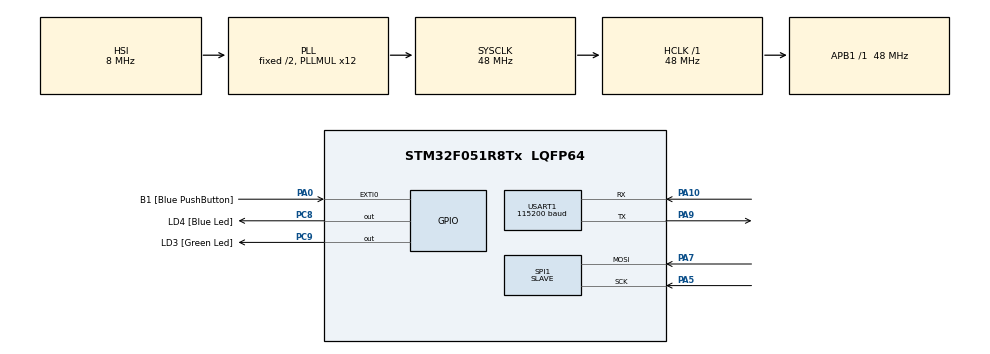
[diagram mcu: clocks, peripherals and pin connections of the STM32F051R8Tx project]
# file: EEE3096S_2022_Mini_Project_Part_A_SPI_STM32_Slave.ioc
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Dma.Request0=SPI1_RX
Dma.SPI1_RX.0.Direction=DMA_PERIPH_TO_MEMORY
Dma.SPI1_RX.0.Instance=DMA1_Channel2
Dma.SPI1_RX.0.MemDataAlignment=DMA_MDATAALIGN_BYTE
Dma.SPI1_RX.0.MemInc=DMA_MINC_ENABLE
Dma.SPI1_RX.0.Mode=DMA_CIRCULAR
Dma.SPI1_RX.0.PeriphDataAlignment=DMA_PDATAALIGN_BYTE
Dma.SPI1_RX.0.PeriphInc=DMA_PINC_DISABLE
Dma.SPI1_RX.0.Priority=DMA_PRIORITY_LOW
Mcu.Family=STM32F0
Mcu.Name=STM32F051R8Tx
Mcu.Package=LQFP64
NVIC.DMA1_Channel2_3_IRQn=true\:0\:0\:false\:false\:true\:false\:true\:true
NVIC.SPI1_IRQn=true\:0\:0\:false\:false\:true\:true\:true\:true
PA0.GPIO_Label=B1 [Blue PushButton]
PA0.GPIO_ModeDefaultEXTI=GPIO_MODE_EVT_RISING
PA0.Signal=GPXTI0
PA10.Mode=Asynchronous
PA10.Signal=USART1_RX
PA13.GPIO_Label=SWDIO
PA13.Mode=Serial_Wire
PA13.Signal=SYS_SWDIO
PA14.GPIO_Label=SWCLK
PA14.Mode=Serial_Wire
PA14.Signal=SYS_SWCLK
PA5.Mode=RX_Only_Simplex_Unidirect_Slave
PA5.Signal=SPI1_SCK
PA7.Mode=RX_Only_Simplex_Unidirect_Slave
PA7.Signal=SPI1_MOSI
PA9.Mode=Asynchronous
PA9.Signal=USART1_TX
PC8.GPIO_Label=LD4 [Blue Led]
PC8.Signal=GPIO_Output
PC9.GPIO_Label=LD3 [Green Led]
PC9.Signal=GPIO_Output
ProjectManager.HeapSize=0x200
ProjectManager.StackSize=0x400
ProjectManager.TargetToolchain=STM32CubeIDE
RCC.AHBFreq_Value=48000000
RCC.APB1Freq_Value=48000000
RCC.APB1TimFreq_Value=48000000
RCC.HCLKFreq_Value=48000000
RCC.PLLMUL=RCC_PLL_MUL12
RCC.SYSCLKFreq_VALUE=48000000
RCC.SYSCLKSource=RCC_SYSCLKSOURCE_PLLCLK
SPI1.DataSize=SPI_DATASIZE_8BIT
SPI1.Direction=SPI_DIRECTION_2LINES_RXONLY
SPI1.Mode=SPI_MODE_SLAVE
SPI1.VirtualType=VM_SLAVE
USART1.BaudRate=115200
USART1.VirtualMode-Asynchronous=VM_ASYNC
board=STM32F0DISCOVERY

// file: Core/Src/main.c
/* USER CODE BEGIN Header */
/**
  ******************************************************************************
  * @file           : main.c
  * @brief          : Main program body
  ******************************************************************************
  * @attention
  *
  * Copyright (c) 2022 STMicroelectronics.
  * All rights reserved.
  *
  * This software is licensed under terms that can be found in the LICENSE file
  * in the root directory of this software component.
  * If no LICENSE file comes with this software, it is provided AS-IS.
  *
  ******************************************************************************
  */
/* USER CODE END Header */
#include "main.h"

SPI_HandleTypeDef hspi1;
DMA_HandleTypeDef hdma_spi1_rx;

UART_HandleTypeDef huart1;
uint8_t RX_Data[1652] = {0};

void SystemClock_Config(void);
static void MX_GPIO_Init(void);
static void MX_DMA_Init(void);
static void MX_SPI1_Init(void);
static void MX_USART1_UART_Init(void);

int main(void)
{

  /* MCU Configuration--------------------------------------------------------*/

  /* Reset of all peripherals, Initializes the Flash interface and the Systick. */
  HAL_Init();

  /* Configure the system clock */
  SystemClock_Config();

  /* Initialize all configured peripherals */
  MX_GPIO_Init();
  MX_DMA_Init();
  MX_SPI1_Init();
  MX_USART1_UART_Init();
  /* USER CODE BEGIN 2 */
  // Receive SPI Data (Blocking Mode) Polling
  HAL_SPI_Receive(&hspi1, RX_Data, sizeof(RX_Data), 5000);
  HAL_UART_Transmit(&huart1, RX_Data, sizeof(RX_Data), 5000);
  for(volatile uint8_t i=0;i<16;i++)
    {
  	  HAL_GPIO_TogglePin(GPIOC, GPIO_PIN_8);
  	  HAL_Delay(1000);
  }
  HAL_GPIO_WritePin(GPIOC, GPIO_PIN_8, GPIO_PIN_RESET);
  /* USER CODE END 2 */

  /* Infinite loop */
  while (1)
  {

  }
}

void SystemClock_Config(void)
{
  RCC_OscInitTypeDef RCC_OscInitStruct = {0};
  RCC_ClkInitTypeDef RCC_ClkInitStruct = {0};
  RCC_PeriphCLKInitTypeDef PeriphClkInit = {0};

  /** Initializes the RCC Oscillators according to the specified parameters
  * in the RCC_OscInitTypeDef structure.
  */
  RCC_OscInitStruct.OscillatorType = RCC_OSCILLATORTYPE_HSI;
  RCC_OscInitStruct.HSIState = RCC_HSI_ON;
  RCC_OscInitStruct.HSICalibrationValue = RCC_HSICALIBRATION_DEFAULT;
  RCC_OscInitStruct.PLL.PLLState = RCC_PLL_ON;
  RCC_OscInitStruct.PLL.PLLSource = RCC_PLLSOURCE_HSI;
  RCC_OscInitStruct.PLL.PLLMUL = RCC_PLL_MUL12;
  RCC_OscInitStruct.PLL.PREDIV = RCC_PREDIV_DIV1;
  if (HAL_RCC_OscConfig(&RCC_OscInitStruct) != HAL_OK)
  {
    Error_Handler();
  }

  /** Initializes the CPU, AHB and APB buses clocks
  */
  RCC_ClkInitStruct.ClockType = RCC_CLOCKTYPE_HCLK|RCC_CLOCKTYPE_SYSCLK
                              |RCC_CLOCKTYPE_PCLK1;
  RCC_ClkInitStruct.SYSCLKSource = RCC_SYSCLKSOURCE_PLLCLK;
  RCC_ClkInitStruct.AHBCLKDivider = RCC_SYSCLK_DIV1;
  RCC_ClkInitStruct.APB1CLKDivider = RCC_HCLK_DIV1;

  if (HAL_RCC_ClockConfig(&RCC_ClkInitStruct, FLASH_LATENCY_1) != HAL_OK)
  {
    Error_Handler();
  }
  PeriphClkInit.PeriphClockSelection = RCC_PERIPHCLK_USART1;
  PeriphClkInit.Usart1ClockSelection = RCC_USART1CLKSOURCE_PCLK1;
  if (HAL_RCCEx_PeriphCLKConfig(&PeriphClkInit) != HAL_OK)
  {
    Error_Handler();
  }
}

static void MX_SPI1_Init(void)
{

  /* SPI1 parameter configuration*/
  hspi1.Instance = SPI1;
  hspi1.Init.Mode = SPI_MODE_SLAVE;
  hspi1.Init.Direction = SPI_DIRECTION_2LINES_RXONLY;
  hspi1.Init.DataSize = SPI_DATASIZE_8BIT;
  hspi1.Init.CLKPolarity = SPI_POLARITY_LOW;
  hspi1.Init.CLKPhase = SPI_PHASE_1EDGE;
  hspi1.Init.NSS = SPI_NSS_SOFT;
  hspi1.Init.FirstBit = SPI_FIRSTBIT_MSB;
  hspi1.Init.TIMode = SPI_TIMODE_DISABLE;
  hspi1.Init.CRCCalculation = SPI_CRCCALCULATION_DISABLE;
  hspi1.Init.CRCPolynomial = 7;
  hspi1.Init.CRCLength = SPI_CRC_LENGTH_DATASIZE;
  hspi1.Init.NSSPMode = SPI_NSS_PULSE_DISABLE;
  if (HAL_SPI_Init(&hspi1) != HAL_OK)
  {
    Error_Handler();
  }

}

static void MX_USART1_UART_Init(void)
{

  huart1.Instance = USART1;
  huart1.Init.BaudRate = 115200;
  huart1.Init.WordLength = UART_WORDLENGTH_8B;
  huart1.Init.StopBits = UART_STOPBITS_1;
  huart1.Init.Parity = UART_PARITY_NONE;
  huart1.Init.Mode = UART_MODE_TX_RX;
  huart1.Init.HwFlowCtl = UART_HWCONTROL_NONE;
  huart1.Init.OverSampling = UART_OVERSAMPLING_16;
  huart1.Init.OneBitSampling = UART_ONE_BIT_SAMPLE_DISABLE;
  huart1.AdvancedInit.AdvFeatureInit = UART_ADVFEATURE_NO_INIT;
  if (HAL_UART_Init(&huart1) != HAL_OK)
  {
    Error_Handler();
  }

}

static void MX_DMA_Init(void)
{

  /* DMA controller clock enable */
  __HAL_RCC_DMA1_CLK_ENABLE();

  /* DMA interrupt init */
  /* DMA1_Channel2_3_IRQn interrupt configuration */
  HAL_NVIC_SetPriority(DMA1_Channel2_3_IRQn, 0, 0);
  HAL_NVIC_EnableIRQ(DMA1_Channel2_3_IRQn);

}

static void MX_GPIO_Init(void)
{
  GPIO_InitTypeDef GPIO_InitStruct = {0};

  /* GPIO Ports Clock Enable */
  __HAL_RCC_GPIOA_CLK_ENABLE();
  __HAL_RCC_GPIOC_CLK_ENABLE();

  /*Configure GPIO pin Output Level */
  HAL_GPIO_WritePin(GPIOC, LD4_Pin|LD3_Pin, GPIO_PIN_RESET);

  /*Configure GPIO pin : B1_Pin */
  GPIO_InitStruct.Pin = B1_Pin;
  GPIO_InitStruct.Mode = GPIO_MODE_EVT_RISING;
  GPIO_InitStruct.Pull = GPIO_NOPULL;
  HAL_GPIO_Init(B1_GPIO_Port, &GPIO_InitStruct);

  /*Configure GPIO pins : LD4_Pin LD3_Pin */
  GPIO_InitStruct.Pin = LD4_Pin|LD3_Pin;
  GPIO_InitStruct.Mode = GPIO_MODE_OUTPUT_PP;
  GPIO_InitStruct.Pull = GPIO_NOPULL;
  GPIO_InitStruct.Speed = GPIO_SPEED_FREQ_LOW;
  HAL_GPIO_Init(GPIOC, &GPIO_InitStruct);

}

void Error_Handler(void)
{
  __disable_irq();
  while (1)
  {
  }
}
